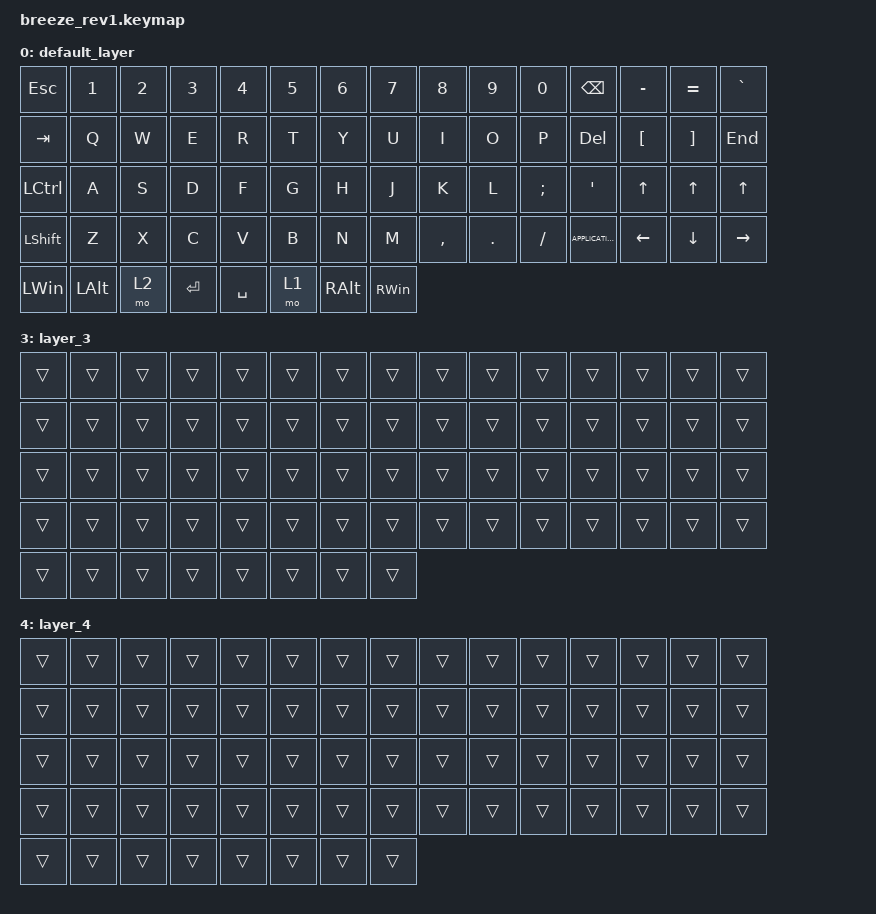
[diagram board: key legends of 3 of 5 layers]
/*
 * Copyright (c) 2022 The ZMK Contributors
 *
 * SPDX-License-Identifier: MIT
 */

#include <behaviors.dtsi>
#include <dt-bindings/zmk/bt.h>
#include <dt-bindings/zmk/keys.h>

/ {
    keymap {
        compatible = "zmk,keymap";

        default_layer {
            // Ref: https://zmkfirmware.dev/docs/codes/
            // ---  MAIN  -----------------------------------------------------------------------------------------------------------------------
            // |    ESC    |     1     |     2     |     3      |      4      |      5     |                           |      6      |      7     |      8      |      9     |     0    |    BSPC    | |    -/_    |     =/+     |    GRAVE    |
            // |    TAB    |     Q     |     W     |     E      |      R      |      T     |                           |      Y      |      U     |      I      |      O     |     P    |    DEL     | |     \     |      [      |      ]      |
            // |   LCTRL   |     A     |     S     |     D      |      F      |      G     |                           |      H      |      J     |      K      |      L     |     ;    |     '      | |           |      UP     |             |
            // |   SHIFT   |     Z     |     X     |     C      |      V      |      B     |                           |      N      |      M     |      ,      |      .     |     /    |   RSHIFT   | |     L     |      DN     |      R      |
            //                                     |   NUMPAD   |     LALT    |    LCMD    |   SPACE    |  |   ENTER   |   FUNCTION  |  MACOS APP |  MACOS LANG |

            bindings = <
&kp ESC           &kp N1    &kp N2  &kp N3     &kp N4     &kp N5  &kp N6    &kp N7    &kp N8     &kp N9   &kp N0    &kp BSPC           &kp MINUS         &kp EQUAL          &kp GRAVE
&kp TAB           &kp Q     &kp W   &kp E      &kp R      &kp T   &kp Y     &kp U     &kp I      &kp O    &kp P     &kp DEL            &kp LEFT_BRACKET  &kp RIGHT_BRACKET  &kp END
&kp LEFT_CONTROL  &kp A     &kp S   &kp D      &kp F      &kp G   &kp H     &kp J     &kp K      &kp L    &kp SEMI  &kp APOS           &kp UP            &kp UP             &kp UP
&kp LEFT_SHIFT    &kp Z     &kp X   &kp C      &kp V      &kp B   &kp N     &kp M     &kp COMMA  &kp DOT  &kp FSLH  &kp K_APPLICATION  &kp LEFT          &kp DOWN           &kp RIGHT
&kp LEFT_WIN      &kp LALT  &mo 2   &kp ENTER  &kp SPACE  &mo 1   &kp RALT  &kp RWIN
            >;
        };

        function_layer {
            // ---  FUNCTION  -------------------------------------------------------------------------------------------------------------------
            // | BT Clear  |  BT Prev  |  BT Next  |            |             |            |                           |             |            |             |            |          |            | |           |             |             |
            // |           |           |           |            |             |            |                           |             |            |     UP      |            |          |            | |           |             |             |
            // |           |           |           |            |             |            |                           |             |    LEFT    |    DOWN     |   RIGHT    |          |            | |           |             |             |
            // |           |           |           |            |             |            |                           |             |    MUTE    |  VOL DOWN   |   VOL UP   |          |            | |           |             |             |
            //                                     |            |             |            |            |  |           |             |            |             |

            bindings = <
&kp F12       &kp F1        &kp F2         &kp F3    &kp F4     &kp F5            &kp F6             &kp F7     &kp F8     &kp F9     &kp F10  &kp F11        &trans  &trans  &trans
&kp C_VOL_DN  &kp C_VOL_UP  &kp PAGE_DOWN  &kp UP    &kp PG_UP  &trans            &trans             &kp KP_N7  &kp KP_N8  &kp KP_N9  &trans   &kp BACKSLASH  &trans  &trans  &trans
&trans        &kp K_MUTE    &kp LEFT       &kp DOWN  &kp RIGHT  &kp LEFT_BRACE    &kp RIGHT_BRACKET  &kp KP_N4  &kp KP_N5  &kp KP_N6  &trans   &trans         &trans  &trans  &trans
&bt BT_CLR    &bt BT_PRV    &bt BT_NXT     &trans    &trans     &kp LEFT_BRACKET  &kp RIGHT_BRACE    &kp KP_N1  &kp KP_N2  &kp KP_N3  &trans   &trans         &trans  &trans  &trans
&trans        &trans        &trans         &trans    &trans     &trans
            >;
        };

        numpad_layer {
            // ---  NUMPAD  -------------------------------------------------------------------------------------------------------------------
            // |           |           |           |            |             |            |                           |       =       |      /       |      *       |      -     |          |            | |           |             |             |
            // |           |           |           |            |             |            |                           |       7       |      8       |      9       |      +     |          |            | |           |             |             |
            // |           |           |           |            |             |            |                           |       4       |      5       |      6       |            |          |            | |           |             |             |
            // |           |           |           |            |             |            |                           |       1       |      2       |      3       |            |          |            | |           |             |             |
            //                                     |            |             |            |            |  |           |       0       |      .       |              |

            bindings = <
&studio_unlock  &trans  &trans  &trans           &trans           &trans          &kp EQUAL        &kp SLASH        &kp STAR         &kp MINUS  &trans  &trans  &trans  &trans  &trans
&trans  &trans  &trans  &trans           &trans           &trans          &kp KP_NUMBER_7  &kp KP_NUMBER_8  &kp KP_NUMBER_9  &kp PLUS   &trans  &trans  &trans  &trans  &trans
&trans  &trans  &trans  &trans           &trans           &kp UNDERSCORE  &kp PLUS         &kp KP_NUMBER_5  &kp KP_NUMBER_6  &trans     &trans  &trans  &trans  &trans  &trans
&trans  &trans  &trans  &trans           &kp KP_NUMBER_1  &kp MINUS       &kp EQUAL        &trans           &trans           &trans     &trans  &trans  &trans  &trans  &trans
&trans  &trans  &trans  &kp KP_NUMBER_0  &kp KP_DOT       &trans
            >;
        };

        layer_3 {
            bindings = <
&trans  &trans  &trans  &trans  &trans  &trans  &trans  &trans  &trans  &trans  &trans  &trans  &trans  &trans  &trans
&trans  &trans  &trans  &trans  &trans  &trans  &trans  &trans  &trans  &trans  &trans  &trans  &trans  &trans  &trans
&trans  &trans  &trans  &trans  &trans  &trans  &trans  &trans  &trans  &trans  &trans  &trans  &trans  &trans  &trans
&trans  &trans  &trans  &trans  &trans  &trans  &trans  &trans  &trans  &trans  &trans  &trans  &trans  &trans  &trans
&trans  &trans  &trans  &trans  &trans  &trans  &trans  &trans
            >;
        };

        layer_4 {
            bindings = <
&trans  &trans  &trans  &trans  &trans  &trans  &trans  &trans  &trans  &trans  &trans  &trans  &trans  &trans  &trans
&trans  &trans  &trans  &trans  &trans  &trans  &trans  &trans  &trans  &trans  &trans  &trans  &trans  &trans  &trans
&trans  &trans  &trans  &trans  &trans  &trans  &trans  &trans  &trans  &trans  &trans  &trans  &trans  &trans  &trans
&trans  &trans  &trans  &trans  &trans  &trans  &trans  &trans  &trans  &trans  &trans  &trans  &trans  &trans  &trans
&trans  &trans  &trans  &trans  &trans  &trans  &trans  &trans
            >;
        };
    };
};
